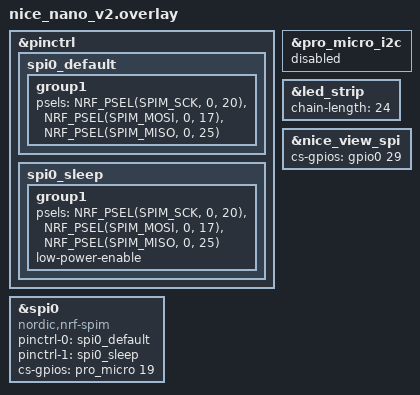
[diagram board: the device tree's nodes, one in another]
/*
 * Board-specific overlay for nice!nano v2 builds
 * Applied to all nice_nano builds regardless of shield
 * This avoids conflicts with xiao_ble dongle builds
 */

// SPI0 configuration for nice_view display
// From: https://github.com/zmkfirmware/zmk/blob/main/app/boards/shields/nice_view_adapter/boards/nice_nano_v2.overlay
&pinctrl {
    spi0_default: spi0_default {
        group1 {
            psels = <NRF_PSEL(SPIM_SCK, 0, 20)>,
                <NRF_PSEL(SPIM_MOSI, 0, 17)>,
                <NRF_PSEL(SPIM_MISO, 0, 25)>;
        };
    };
    spi0_sleep: spi0_sleep {
        group1 {
            psels = <NRF_PSEL(SPIM_SCK, 0, 20)>,
                <NRF_PSEL(SPIM_MOSI, 0, 17)>,
                <NRF_PSEL(SPIM_MISO, 0, 25)>;
            low-power-enable;
        };
    };
};

&spi0 {
    compatible = "nordic,nrf-spim";
    pinctrl-0 = <&spi0_default>;
    pinctrl-1 = <&spi0_sleep>;
    pinctrl-names = "default", "sleep";
    cs-gpios = <&pro_micro 19 GPIO_ACTIVE_HIGH>;
};

&pro_micro_i2c {
    status = "disabled";
};

/* RGB LED strip configuration for Aurora Corne */
&led_strip { chain-length = <24>; };

/* nice!view display CS pin assignment */
&nice_view_spi {
    cs-gpios = <&gpio0 29 GPIO_ACTIVE_HIGH>; // Assigning CS to D20
};
